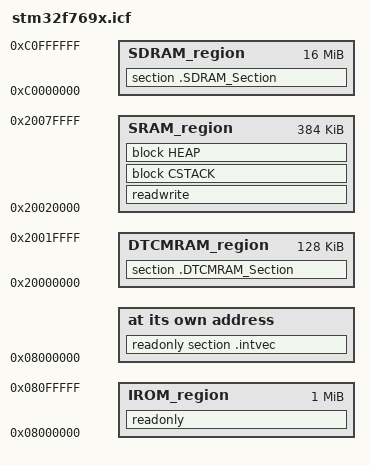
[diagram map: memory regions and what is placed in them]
/*###ICF### Section handled by ICF editor, don't touch! ****/
/*-Editor annotation file-*/
/* IcfEditorFile="$TOOLKIT_DIR$\config\ide\IcfEditor\cortex_v1_1.xml" */
/*-Specials-*/
define symbol __ICFEDIT_intvec_start__ = 0x08000000;

/*-Memory Regions-*/
define symbol __ICFEDIT_region_IROM1_start__   = 0x08000000;
define symbol __ICFEDIT_region_IROM1_end__     = 0x080FFFFF;
define symbol __ICFEDIT_region_IRAM1_start__   = 0x20020000;
define symbol __ICFEDIT_region_IRAM1_end__     = 0x2007FFFF;
define symbol __ICFEDIT_region_ERAM1_start__   = 0xC0000000;
define symbol __ICFEDIT_region_ERAM1_end__     = 0xC0FFFFFF;
define symbol __ICFEDIT_region_DTCMRAM_start__ = 0x20000000;
define symbol __ICFEDIT_region_DTCMRAM_end__   = 0x2001FFFF;

/*-Sizes-*/
define symbol __ICFEDIT_size_cstack__ = 0x2000;
define symbol __ICFEDIT_size_heap__   = 0x100;
/**** End of ICF editor section. ###ICF###*/

define memory mem with size = 4G;
define region IROM_region     = mem:[from __ICFEDIT_region_IROM1_start__ to __ICFEDIT_region_IROM1_end__];
define region SRAM_region     = mem:[from __ICFEDIT_region_IRAM1_start__ to __ICFEDIT_region_IRAM1_end__];
define region SDRAM_region    = mem:[from __ICFEDIT_region_ERAM1_start__ to __ICFEDIT_region_ERAM1_end__];
define region DTCMRAM_region  = mem:[from __ICFEDIT_region_DTCMRAM_start__ to __ICFEDIT_region_DTCMRAM_end__];

define block CSTACK with alignment = 8, size = __ICFEDIT_size_cstack__ { };
define block HEAP   with alignment = 8, size = __ICFEDIT_size_heap__ { };

initialize by copy { readwrite };
//initialize by copy with packing = none { section __DLIB_PERTHREAD }; // Required in a multi-threaded application
do not initialize  { section .noinit };
do not initialize  { section .SDRAM_Section };

place at address mem:__ICFEDIT_intvec_start__ { readonly section .intvec };

place in IROM_region  { readonly };
place in SRAM_region  { readwrite, block CSTACK, block HEAP };
place in SDRAM_region  { section .SDRAM_Section };
place in DTCMRAM_region  { section .DTCMRAM_Section };
